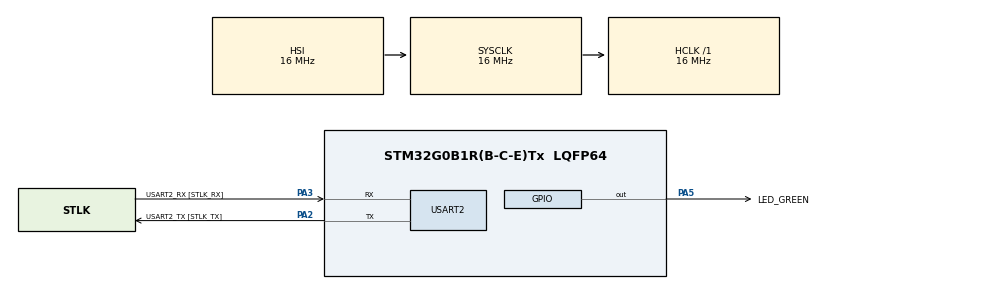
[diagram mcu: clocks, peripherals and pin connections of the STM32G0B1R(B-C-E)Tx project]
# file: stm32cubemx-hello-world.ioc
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Mcu.Family=STM32G0
Mcu.Name=STM32G0B1R(B-C-E)Tx
Mcu.Package=LQFP64
PA13.GPIO_Label=TMS
PA13.Mode=Serial_Wire
PA13.Signal=SYS_SWDIO
PA14-BOOT0.GPIO_Label=TCK
PA14-BOOT0.Mode=Serial_Wire
PA14-BOOT0.Signal=SYS_SWCLK
PA2.GPIO_Label=USART2_TX [STLK_TX]
PA2.Mode=Asynchronous
PA2.Signal=USART2_TX
PA3.GPIO_Label=USART2_RX [STLK_RX]
PA3.Mode=Asynchronous
PA3.Signal=USART2_RX
PA5.GPIO_Label=LED_GREEN
PA5.GPIO_Speed=GPIO_SPEED_FREQ_HIGH
PA5.Signal=GPIO_Output
PC13.Mode=SYS_WakeUp1
PC13.Signal=SYS_WKUP2
PC14-OSC32_IN\ (PC14).Mode=LSE-External-Oscillator
PC14-OSC32_IN\ (PC14).Signal=RCC_OSC32_IN
PC15-OSC32_OUT\ (PC15).Mode=LSE-External-Oscillator
PC15-OSC32_OUT\ (PC15).Signal=RCC_OSC32_OUT
PF0-OSC_IN\ (PF0).GPIO_Label=MCO
PF0-OSC_IN\ (PF0).Mode=HSE-External-Clock-Source
PF0-OSC_IN\ (PF0).Signal=RCC_OSC_IN
ProjectManager.HeapSize=0x200
ProjectManager.StackSize=0x400
ProjectManager.TargetToolchain=Other Toolchains (GPDSC)
RCC.AHBFreq_Value=16000000
RCC.CortexFreq_Value=16000000
RCC.EXTERNAL_CLOCK_VALUE=12288000
RCC.HCLKFreq_Value=16000000
RCC.HSI48_VALUE=48000000
RCC.HSI_VALUE=16000000
RCC.SYSCLKFreq_VALUE=16000000
RCC.USBFreq_Value=48000000
RCC.VCOOutputFreq_Value=128000000
USART2.VirtualMode-Asynchronous=VM_ASYNC
VP_SYS_VS_DBSignals.Mode=DisableDeadBatterySignals
board=NUCLEO-G0B1RE

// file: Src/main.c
/* USER CODE BEGIN Header */
/**
  ******************************************************************************
  * @file           : main.c
  * @brief          : Main program body
  ******************************************************************************
  * @attention
  *
  * Copyright (c) 2022 STMicroelectronics.
  * All rights reserved.
  *
  * This software is licensed under terms that can be found in the LICENSE file
  * in the root directory of this software component.
  * If no LICENSE file comes with this software, it is provided AS-IS.
  *
  ******************************************************************************
  */
/* USER CODE END Header */
#include "main.h"
#include "usart.h"
#include "gpio.h"

void SystemClock_Config(void);

int main(void)
{

  /* MCU Configuration--------------------------------------------------------*/

  /* Reset of all peripherals, Initializes the Flash interface and the Systick. */
  HAL_Init();

  /* Configure the system clock */
  SystemClock_Config();

  /* Initialize all configured peripherals */
  MX_GPIO_Init();
  MX_USART2_UART_Init();

  /* Infinite loop */
  /* USER CODE BEGIN WHILE */
  while (1)
  {
    HAL_GPIO_TogglePin(LED_GREEN_GPIO_Port, LED_GREEN_Pin);
    HAL_Delay(100);
    /* USER CODE END WHILE */

  }
}

void SystemClock_Config(void)
{
  RCC_OscInitTypeDef RCC_OscInitStruct = {0};
  RCC_ClkInitTypeDef RCC_ClkInitStruct = {0};

  /** Configure the main internal regulator output voltage
  */
  HAL_PWREx_ControlVoltageScaling(PWR_REGULATOR_VOLTAGE_SCALE1);

  /** Initializes the RCC Oscillators according to the specified parameters
  * in the RCC_OscInitTypeDef structure.
  */
  RCC_OscInitStruct.OscillatorType = RCC_OSCILLATORTYPE_HSI;
  RCC_OscInitStruct.HSIState = RCC_HSI_ON;
  RCC_OscInitStruct.HSIDiv = RCC_HSI_DIV1;
  RCC_OscInitStruct.HSICalibrationValue = RCC_HSICALIBRATION_DEFAULT;
  RCC_OscInitStruct.PLL.PLLState = RCC_PLL_NONE;
  if (HAL_RCC_OscConfig(&RCC_OscInitStruct) != HAL_OK)
  {
    Error_Handler();
  }

  /** Initializes the CPU, AHB and APB buses clocks
  */
  RCC_ClkInitStruct.ClockType = RCC_CLOCKTYPE_HCLK|RCC_CLOCKTYPE_SYSCLK
                              |RCC_CLOCKTYPE_PCLK1;
  RCC_ClkInitStruct.SYSCLKSource = RCC_SYSCLKSOURCE_HSI;
  RCC_ClkInitStruct.AHBCLKDivider = RCC_SYSCLK_DIV1;
  RCC_ClkInitStruct.APB1CLKDivider = RCC_HCLK_DIV1;

  if (HAL_RCC_ClockConfig(&RCC_ClkInitStruct, FLASH_LATENCY_0) != HAL_OK)
  {
    Error_Handler();
  }
}

void Error_Handler(void)
{
  __disable_irq();
  while (1)
  {
  }
}

#ifdef  USE_FULL_ASSERT
/**
  * @brief  Reports the name of the source file and the source line number
  *         where the assert_param error has occurred.
  * @param  file: pointer to the source file name
  * @param  line: assert_param error line source number
  * @retval None
  */
void assert_failed(uint8_t *file, uint32_t line)
{
  /* USER CODE BEGIN 6 */
  /* User can add his own implementation to report the file name and line number,
     example: printf("Wrong parameters value: file %s on line %d\r\n", file, line) */
  /* USER CODE END 6 */
}
#endif /* USE_FULL_ASSERT */
